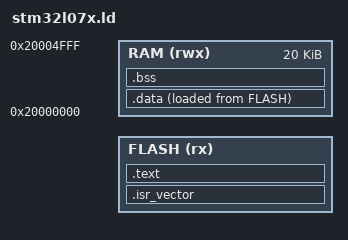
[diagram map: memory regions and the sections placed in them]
/* stm32l07x.ld */

/* Include the shared memory map definitions generated/pre-processed via GCC */
#include "flash_map.h"

ENTRY(Reset_Handler)

MEMORY
{
  /* We define the FLASH memory region for building Slot A */
  FLASH (rx) : ORIGIN = SLOT_A_START, LENGTH = SLOT_A_SIZE
  RAM (rwx)  : ORIGIN = 0x20000000, LENGTH = 20K
}

_estack = ORIGIN(RAM) + LENGTH(RAM);

SECTIONS
{
  .isr_vector :
  {
    . = ALIGN(4);
    KEEP(*(.isr_vector))
    . = ALIGN(4);
  } >FLASH

  .text :
  {
    . = ALIGN(4);
    *(.text)
    *(.text*)
    *(.rodata)
    *(.rodata*)
    . = ALIGN(4);
    _etext = .;
  } >FLASH

  _sidata = LOADADDR(.data);

  .data :
  {
    . = ALIGN(4);
    _sdata = .;
    *(.data)
    *(.data*)
    . = ALIGN(4);
    _edata = .;
  } >RAM AT> FLASH

  .bss :
  {
    . = ALIGN(4);
    _sbss = .;
    __bss_start__ = _sbss;
    *(.bss)
    *(.bss*)
    *(COMMON)
    . = ALIGN(4);
    _ebss = .;
    __bss_end__ = _ebss;
  } >RAM
}
